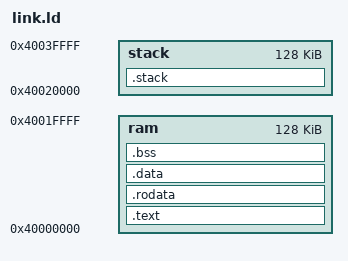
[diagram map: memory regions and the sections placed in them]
/* Copyright lowRISC contributors.
   Licensed under the Apache License, Version 2.0, see LICENSE for details.
   SPDX-License-Identifier: Apache-2.0 */

OUTPUT_ARCH(riscv)

MEMORY
{
    /* 60 KiB should be enough for anybody... */
    ram         : ORIGIN = 0x40000000, LENGTH = 0x20000 /* 128 KiB */
    stack       : ORIGIN = 0x40020000, LENGTH = 0x20000  /* 128 KiB */
}

/* Stack information variables */
_min_stack      = 0x10000;   /* 64K - minimum stack space to reserve */
_stack_len     = LENGTH(stack);
_stack_start   = ORIGIN(stack) + LENGTH(stack);

_entry_point = _vectors_start + 0x80;
ENTRY(_entry_point)

SECTIONS
{
    .text : {
        . = ALIGN(4);
		_vectors_start = .;
        KEEP(*(.vectors))
		_vectors_end = .;
        *(.text)
        *(.text.*)
        . = ALIGN(4);
    }  > ram

    .rodata : {
        . = ALIGN(4);
        /* Small RO data before large RO data */
        *(.srodata)
        *(.srodata.*)
        *(.rodata);
        *(.rodata.*)
        . = ALIGN(4);
    } > ram

    .data : {
        . = ALIGN(4);
        /* Small data before large data */
        *(.sdata)
        *(.sdata.*)
        *(.data);
        *(.data.*)
        . = ALIGN(4);
    } > ram

    .bss :
    {
        . = ALIGN(4);
        _bss_start = .;
        /* Small BSS before large BSS */
        *(.sbss)
        *(.sbss.*)
        *(.bss)
        *(.bss.*)
        *(COMMON)
        _bss_end = .;
        . = ALIGN(4);
    } > ram

    /* ensure there is enough room for stack */
    .stack (NOLOAD): {
        . = ALIGN(4);
        . = . + _min_stack ;
        . = ALIGN(4);
        stack = . ;
        _stack = . ;
    } > stack
}
